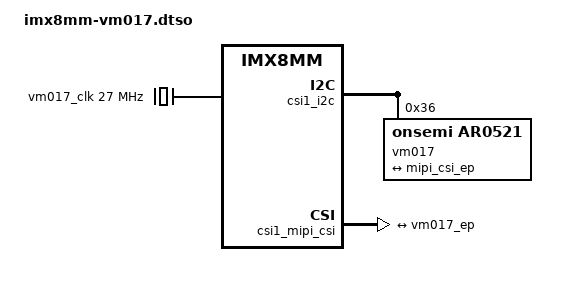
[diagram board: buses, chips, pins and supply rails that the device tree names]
// SPDX-License-Identifier: (GPL-2.0+ OR MIT)
/*
 * Copyright (C) 2021 PHYTEC Messtechnik GmbH
 * Author: Stefan Riedmueller <s.riedmueller@phytec.de>
 */

/dts-v1/;
/plugin/;

/ {
	compatible = "phytec,imx8mm-phyboard-polis";
};

&{/} {
	vm017_clk: vm017-ext-clk {
		#clock-cells = <0>;
		compatible = "fixed-clock";
		clock-frequency = <27000000>;
	};
};

&csi1_i2c {
	#address-cells = <1>;
	#size-cells = <0>;

	status = "okay";

	vm017: camera@36 {
		#address-cells = <0x1>;
		#size-cells = <0x0>;

		compatible = "onsemi,ar0521";
		reg = <0x36>;
		clock-names = "ext";
		clocks = <&vm017_clk>;

		port@0 {
			reg = <0>;

			vm017_ep: endpoint {
				remote-endpoint = <&mipi_csi_ep>;
				bus-type = <4>; /* MIPI CSI-2 D-PHY */
				link-frequencies = /bits/ 64 <504000000>;
				data-lanes = <1 2 3 4>;
				clock-lanes = <0>;
				clock-noncontinuous = <1>;
			};
		};
	};
};

&csi1_mipi_csi {
	port@0 {
		mipi_csi_ep: endpoint {
			remote-endpoint = <&vm017_ep>;
			data-lanes = <1 2 3 4>;
		};
	};
};
